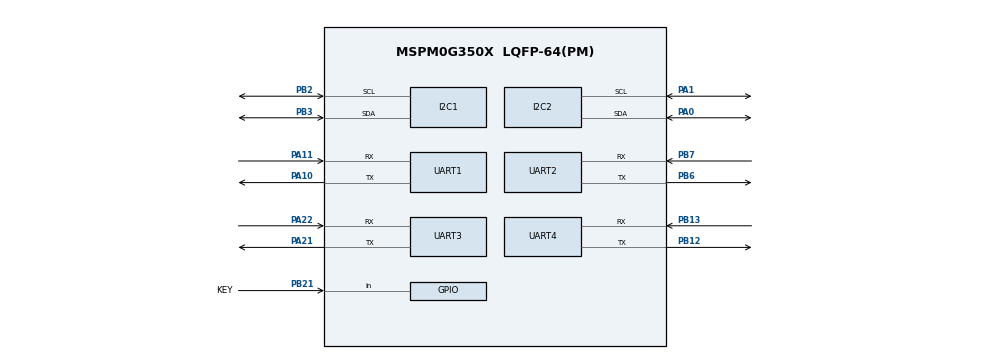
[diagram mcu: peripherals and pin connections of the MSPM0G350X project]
/**
 *
 * @cliArgs --device "MSPM0G350X" --part "Default" --package "LQFP-64(PM)" --product "mspm0_sdk@2.11.00.07"
 * @versions {"tool":"1.28.1+4785"}
 */

/**
 * Import the modules used in this configuration.
 */
const GPIO          = scripting.addModule("/ti/driverlib/GPIO", {}, false);
const GPIO1         = GPIO.addInstance();
const GPIO2         = GPIO.addInstance();
const I2C           = scripting.addModule("/ti/driverlib/I2C", {}, false);
const I2C1          = I2C.addInstance();
const I2C2          = I2C.addInstance();
const SYSCTL        = scripting.addModule("/ti/driverlib/SYSCTL");
const UART          = scripting.addModule("/ti/driverlib/UART", {}, false);
const UART1         = UART.addInstance();
const UART2         = UART.addInstance();
const UART3         = UART.addInstance();
const UART4         = UART.addInstance();
const ProjectConfig = scripting.addModule("/ti/project_config/ProjectConfig");

/**
 * Write custom configuration values to the imported modules.
 */
GPIO1.port                          = "PORTB";
GPIO1.$name                         = "LED_TEST";
GPIO1.associatedPins.create(2);
GPIO1.associatedPins[0].$name       = "BOARD_LED";
GPIO1.associatedPins[0].assignedPin = "22";
GPIO1.associatedPins[1].$name       = "OS_LED";
GPIO1.associatedPins[1].assignedPin = "1";

const Board = scripting.addModule("/ti/driverlib/Board", {}, false);

GPIO2.$name                              = "KEY_DEBUG";
GPIO2.port                               = "PORTB";
GPIO2.portSegment                        = "Upper";
GPIO2.associatedPins[0].assignedPin      = "21";
GPIO2.associatedPins[0].direction        = "INPUT";
GPIO2.associatedPins[0].$name            = "KEY";
GPIO2.associatedPins[0].interruptEn      = true;
GPIO2.associatedPins[0].polarity         = "FALL";
GPIO2.associatedPins[0].internalResistor = "PULL_UP";
GPIO2.associatedPins[0].inputFilter      = "3_CYCLES";
GPIO2.associatedPins[0].pin.$assign      = "PB21";

I2C1.$name                             = "OLED";
I2C1.peripheral.$assign                = "I2C1";
I2C1.peripheral.sdaPin.$assign         = "PB3";
I2C1.peripheral.sclPin.$assign         = "PB2";
I2C1.sdaPinConfig.hideOutputInversion  = scripting.forceWrite(false);
I2C1.sdaPinConfig.onlyInternalResistor = scripting.forceWrite(false);
I2C1.sdaPinConfig.passedPeripheralType = scripting.forceWrite("Digital");
I2C1.sdaPinConfig.$name                = "ti_driverlib_gpio_GPIOPinGeneric8";
I2C1.sclPinConfig.hideOutputInversion  = scripting.forceWrite(false);
I2C1.sclPinConfig.onlyInternalResistor = scripting.forceWrite(false);
I2C1.sclPinConfig.passedPeripheralType = scripting.forceWrite("Digital");
I2C1.sclPinConfig.$name                = "ti_driverlib_gpio_GPIOPinGeneric9";

I2C2.$name                             = "LineFollower";
I2C2.peripheral.$assign                = "I2C0";
I2C2.peripheral.sdaPin.$assign         = "PA0";
I2C2.peripheral.sclPin.$assign         = "PA1";
I2C2.sdaPinConfig.hideOutputInversion  = scripting.forceWrite(false);
I2C2.sdaPinConfig.onlyInternalResistor = scripting.forceWrite(false);
I2C2.sdaPinConfig.passedPeripheralType = scripting.forceWrite("Digital");
I2C2.sdaPinConfig.$name                = "ti_driverlib_gpio_GPIOPinGeneric10";
I2C2.sclPinConfig.hideOutputInversion  = scripting.forceWrite(false);
I2C2.sclPinConfig.onlyInternalResistor = scripting.forceWrite(false);
I2C2.sclPinConfig.passedPeripheralType = scripting.forceWrite("Digital");
I2C2.sclPinConfig.$name                = "ti_driverlib_gpio_GPIOPinGeneric11";


UART1.$name                            = "Debug";
UART1.targetBaudRate                   = 115200;
UART1.peripheral.$assign               = "UART0";
UART1.peripheral.rxPin.$assign         = "PA11";
UART1.peripheral.txPin.$assign         = "PA10";
UART1.txPinConfig.direction            = scripting.forceWrite("OUTPUT");
UART1.txPinConfig.hideOutputInversion  = scripting.forceWrite(false);
UART1.txPinConfig.onlyInternalResistor = scripting.forceWrite(false);
UART1.txPinConfig.passedPeripheralType = scripting.forceWrite("Digital");
UART1.txPinConfig.$name                = "ti_driverlib_gpio_GPIOPinGeneric0";
UART1.rxPinConfig.hideOutputInversion  = scripting.forceWrite(false);
UART1.rxPinConfig.onlyInternalResistor = scripting.forceWrite(false);
UART1.rxPinConfig.passedPeripheralType = scripting.forceWrite("Digital");
UART1.rxPinConfig.$name                = "ti_driverlib_gpio_GPIOPinGeneric1";

UART2.$name                            = "EMM42";
UART2.targetBaudRate                   = 115200;
UART2.peripheral.$assign               = "UART1";
UART2.peripheral.rxPin.$assign         = "PB7";
UART2.peripheral.txPin.$assign         = "PB6";
UART2.txPinConfig.direction            = scripting.forceWrite("OUTPUT");
UART2.txPinConfig.hideOutputInversion  = scripting.forceWrite(false);
UART2.txPinConfig.onlyInternalResistor = scripting.forceWrite(false);
UART2.txPinConfig.passedPeripheralType = scripting.forceWrite("Digital");
UART2.txPinConfig.$name                = "ti_driverlib_gpio_GPIOPinGeneric2";
UART2.rxPinConfig.hideOutputInversion  = scripting.forceWrite(false);
UART2.rxPinConfig.onlyInternalResistor = scripting.forceWrite(false);
UART2.rxPinConfig.passedPeripheralType = scripting.forceWrite("Digital");
UART2.rxPinConfig.$name                = "ti_driverlib_gpio_GPIOPinGeneric3";

UART3.$name                            = "Vision";
UART3.targetBaudRate                   = 115200;
UART3.peripheral.$assign               = "UART2";
UART3.peripheral.rxPin.$assign         = "PA22";
UART3.peripheral.txPin.$assign         = "PA21";
UART3.txPinConfig.direction            = scripting.forceWrite("OUTPUT");
UART3.txPinConfig.hideOutputInversion  = scripting.forceWrite(false);
UART3.txPinConfig.onlyInternalResistor = scripting.forceWrite(false);
UART3.txPinConfig.passedPeripheralType = scripting.forceWrite("Digital");
UART3.txPinConfig.$name                = "ti_driverlib_gpio_GPIOPinGeneric4";
UART3.rxPinConfig.hideOutputInversion  = scripting.forceWrite(false);
UART3.rxPinConfig.onlyInternalResistor = scripting.forceWrite(false);
UART3.rxPinConfig.passedPeripheralType = scripting.forceWrite("Digital");
UART3.rxPinConfig.$name                = "ti_driverlib_gpio_GPIOPinGeneric5";

UART4.$name                             = "IMU";
UART4.enabledDMARXTriggers              = "DL_UART_DMA_INTERRUPT_RX";
UART4.peripheral.$assign                = "UART3";
UART4.peripheral.rxPin.$assign          = "PB13";
UART4.peripheral.txPin.$assign          = "PB12";
UART4.txPinConfig.direction             = scripting.forceWrite("OUTPUT");
UART4.txPinConfig.hideOutputInversion   = scripting.forceWrite(false);
UART4.txPinConfig.onlyInternalResistor  = scripting.forceWrite(false);
UART4.txPinConfig.passedPeripheralType  = scripting.forceWrite("Digital");
UART4.txPinConfig.$name                 = "ti_driverlib_gpio_GPIOPinGeneric6";
UART4.rxPinConfig.hideOutputInversion   = scripting.forceWrite(false);
UART4.rxPinConfig.onlyInternalResistor  = scripting.forceWrite(false);
UART4.rxPinConfig.passedPeripheralType  = scripting.forceWrite("Digital");
UART4.rxPinConfig.$name                 = "ti_driverlib_gpio_GPIOPinGeneric7";
UART4.DMA_CHANNEL_RX.$name              = "DMA_CH0";
UART4.DMA_CHANNEL_RX.addressMode        = "f2b";
UART4.DMA_CHANNEL_RX.srcLength          = "BYTE";
UART4.DMA_CHANNEL_RX.dstLength          = "BYTE";
UART4.DMA_CHANNEL_RX.enableInterrupt    = true;
UART4.DMA_CHANNEL_RX.peripheral.$assign = "DMA_CH0";

ProjectConfig.deviceSpin = "MSPM0G3507";

/**
 * Pinmux solution for unlocked pins/peripherals. This ensures that minor changes to the automatic solver in a future
 * version of the tool will not impact the pinmux you originally saw.  These lines can be completely deleted in order to
 * re-solve from scratch.
 */
GPIO1.associatedPins[0].pin.$suggestSolution = "PB22";
GPIO1.associatedPins[1].pin.$suggestSolution = "PB1";
Board.peripheral.$suggestSolution            = "DEBUGSS";
Board.peripheral.swclkPin.$suggestSolution   = "PA20";
Board.peripheral.swdioPin.$suggestSolution   = "PA19";
SYSCTL.peripheral.$suggestSolution           = "SYSCTL";
